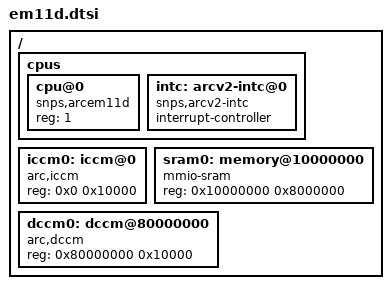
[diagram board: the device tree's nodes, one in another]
#include <emsk.dtsi>

/ {
	cpus {
		#address-cells = <1>;
		#size-cells = <0>;

		cpu@0 {
			device_type = "cpu";
			compatible = "snps,arcem11d";
			reg = <1>;
		};

		intc: arcv2-intc@0 {
			compatible = "snps,arcv2-intc";
			interrupt-controller;
			#interrupt-cells = <2>;
		};
	};

	iccm0: iccm@0 {
		device_type = "memory";
		compatible = "arc,iccm";
		reg = <0x0 0x10000>;
	};

	sram0: memory@10000000 {
		device_type = "memory";
		compatible = "mmio-sram";
		reg = <0x10000000 0x8000000>;
	};

	dccm0: dccm@80000000 {
		device_type = "memory";
		compatible = "arc,dccm";
		reg = <0x80000000 0x10000>;
	};
};
